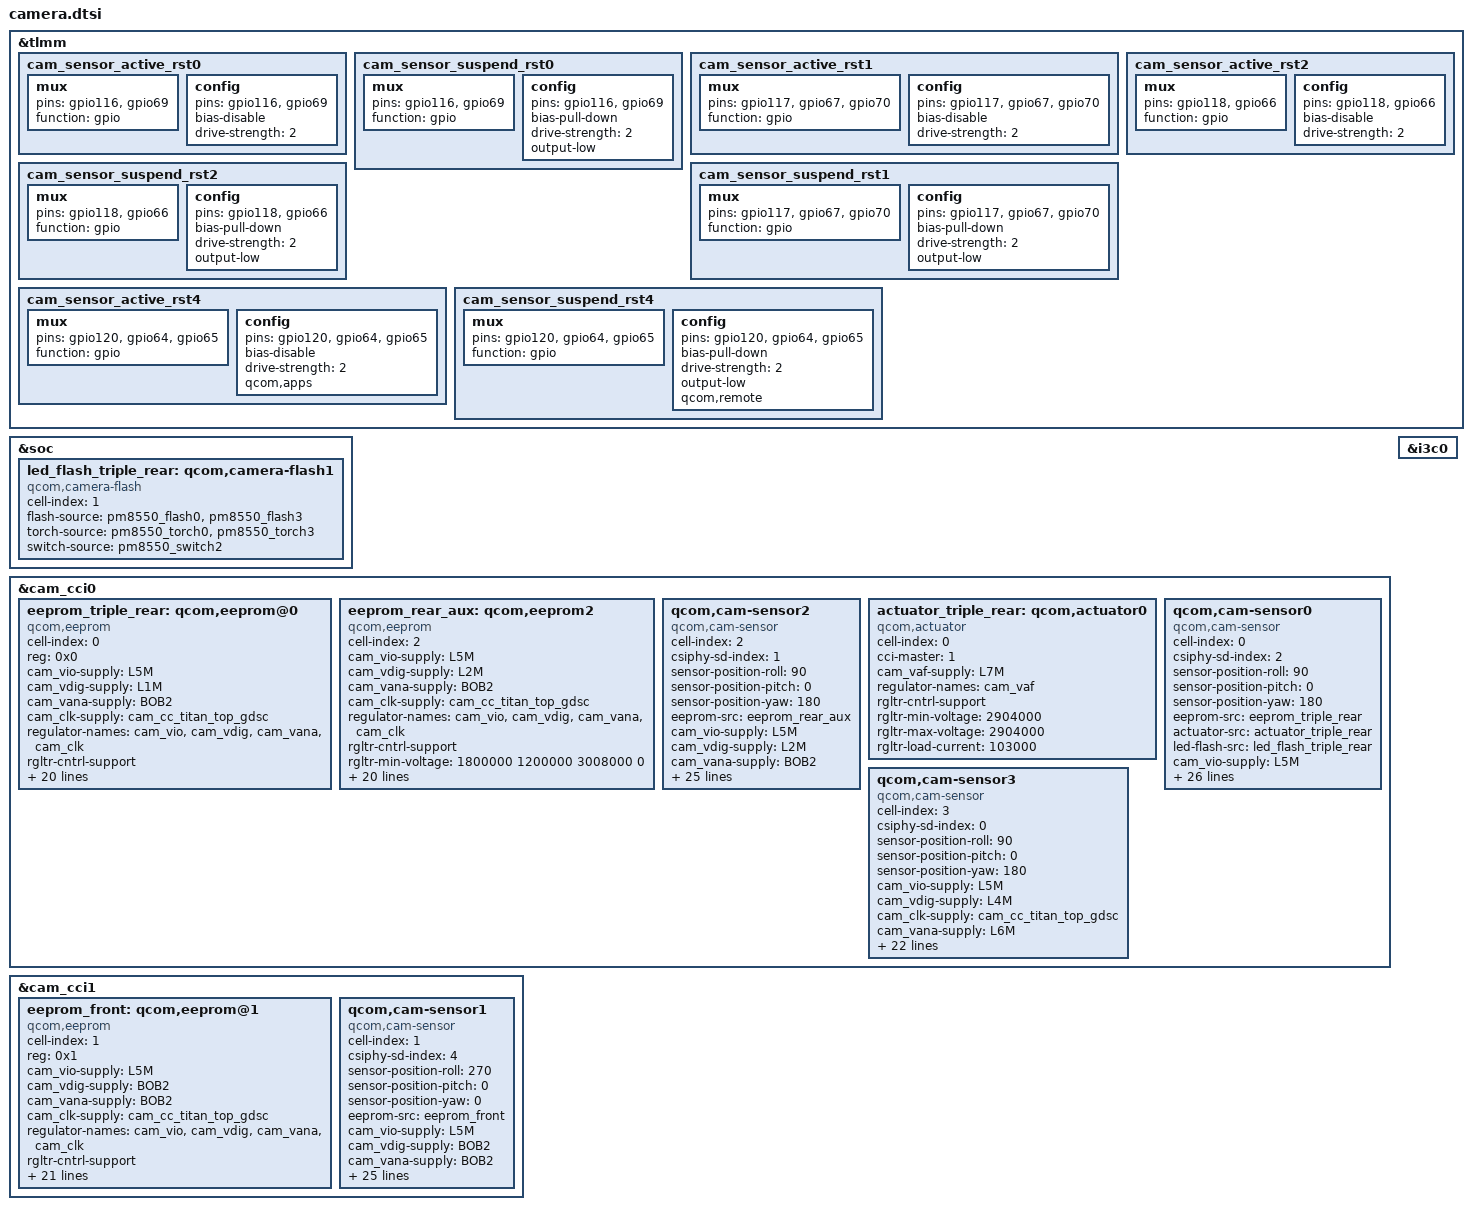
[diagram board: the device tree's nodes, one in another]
//#include <dt-bindings/msm-camera.h>
#include <dt-bindings/clock/qcom,camcc-kalama.h>

&tlmm {
	/delete-node/ cam_sensor_active_rst0;
	/delete-node/ cam_sensor_suspend_rst0;
	/delete-node/ cam_sensor_active_rst1;
	/delete-node/ cam_sensor_suspend_rst1;
	/delete-node/ cam_sensor_active_rst2;
	/delete-node/ cam_sensor_suspend_rst2;
	/delete-node/ cam_sensor_active_rst4;
	/delete-node/ cam_sensor_suspend_rst4;	
	
	cam_sensor_active_rst0: cam_sensor_active_rst0 {
		mux {
			pins = "gpio116","gpio69";
			function = "gpio";
		};

		config {
			pins = "gpio116","gpio69";
			bias-disable; /* No PULL */
			drive-strength = <2>; /* 2 MA */
		};
	};

	cam_sensor_suspend_rst0: cam_sensor_suspend_rst0 {
		mux {
			pins = "gpio116","gpio69";
			function = "gpio";
		};

		config {
			pins = "gpio116","gpio69";
			bias-pull-down; /* PULL DOWN */
			drive-strength = <2>; /* 2 MA */
			output-low;
		};
	};

	cam_sensor_active_rst1: cam_sensor_active_rst1 {
		mux {
			pins = "gpio117","gpio67","gpio70";
			function = "gpio";
		};

		config {
			pins = "gpio117","gpio67","gpio70";
			bias-disable; /* No PULL */
			drive-strength = <2>; /* 2 MA */
		};
	};

	cam_sensor_suspend_rst1: cam_sensor_suspend_rst1 {
		mux {
			pins = "gpio117","gpio67","gpio70";
			function = "gpio";
		};

		config {
			pins = "gpio117","gpio67","gpio70";
			bias-pull-down; /* PULL DOWN */
			drive-strength = <2>; /* 2 MA */
			output-low;
		};
	};

	cam_sensor_active_rst2: cam_sensor_active_rst2 {
		mux {
			pins =  "gpio118","gpio66";
			function = "gpio";
		};

		config {
			pins = "gpio118","gpio66";
			bias-disable; /* No PULL */
			drive-strength = <2>; /* 2 MA */
		};
	};

	cam_sensor_suspend_rst2: cam_sensor_suspend_rst2 {
		mux {
			pins =  "gpio118","gpio66";
			function = "gpio";
		};

		config {
			pins = "gpio118","gpio66";
			bias-pull-down; /* PULL DOWN */
			drive-strength = <2>; /* 2 MA */
			output-low;
		};
	};
		cam_sensor_active_rst4: cam_sensor_active_rst4 {
		mux {
			pins = "gpio120","gpio64","gpio65";
			function = "gpio";
		};

		config {
			pins = "gpio120","gpio64","gpio65";
			bias-disable; /* No PULL */
			drive-strength = <2>; /* 2 MA */
			qcom,apps;
		};
	};

	cam_sensor_suspend_rst4: cam_sensor_suspend_rst4 {
		mux {
			pins = "gpio120","gpio64","gpio65";
			function = "gpio";
		};

		config {
			pins = "gpio120","gpio64","gpio65";
			bias-pull-down; /* PULL DOWN */
			drive-strength = <2>; /* 2 MA */
			output-low;
			qcom,remote;
		};
	};

};


&soc {
	/delete-node/ led_flash_triple_rear_wide;
	/delete-node/ led_flash_triple_rear_tele;
	/delete-node/ led_flash_triple_rear_ultrawide;
	led_flash_triple_rear: qcom,camera-flash1 {
		cell-index = <1>;
		compatible = "qcom,camera-flash";
		flash-source = <&pm8550_flash0 &pm8550_flash3>;
		torch-source = <&pm8550_torch0 &pm8550_torch3>;
		switch-source = <&pm8550_switch2>;
		status = "ok";
	};
};

&cam_cci0 {

	/delete-node/ actuator_triple_uw;
	/delete-node/ actuator_triple_wide;
	/delete-node/ actuator_ois;
	/delete-node/ actuator_hp1;
	/delete-node/ ois0;
	/delete-node/ eeprom_tof1;
	/delete-node/ eeprom_uw;
	/delete-node/ eeprom_wide;
	/delete-node/ eeprom_ois;
	/delete-node/ eeprom_hp1;
	/delete-node/ qcom,cam-sensor7;
	/delete-node/ qcom,cam-sensor1;
	/delete-node/ qcom,cam-sensor2;
	/delete-node/ qcom,cam-sensor9;
	/delete-node/ qcom,cam-sensor0;
	eeprom_triple_rear: qcom,eeprom@0 {
		cell-index = <0>;
		compatible = "qcom,eeprom";
		reg = <0x0>;
		cam_vio-supply = <&L5M>; //dovdd  L5M 1.8v
		cam_vdig-supply = <&L1M>;//dvdd L1M  0.92v
		cam_vana-supply = <&BOB2>;//avdd L3M  2.2v 
		cam_clk-supply = <&cam_cc_titan_top_gdsc>;
		regulator-names = "cam_vio", "cam_vdig", "cam_vana",
			"cam_clk";
		rgltr-cntrl-support;
		rgltr-min-voltage = <1800000 920000 3008000 0>;
		rgltr-max-voltage = <1800000 920000 3960000 0>;
		rgltr-load-current = <10000 140000 7070000 0>;
		gpio-no-mux = <0>;
		pinctrl-names = "cam_default", "cam_suspend";
		pinctrl-0 = <&cam_sensor_mclk2_active
				&cam_sensor_active_rst2>;
		pinctrl-1 = <&cam_sensor_mclk2_suspend
				&cam_sensor_suspend_rst2>;
		gpios = <&tlmm 102 0>,	// mclk  102
		        <&tlmm 118 0>,	// reset  118 		
			<&tlmm 66 0>;	//<&tlmm 66 0>;	

		gpio-reset = <1>;
		gpio-vana = <2>;
		gpio-req-tbl-num = <0 1 2>;
		gpio-req-tbl-flags = <1 0 0>;
		gpio-req-tbl-label = "CAMIF_MCLK0",
					"CAM_RESET0",
					"CAM_VANA0"; //avdd

		cci-master = <1>;
		cci-device = <1>;
		status = "ok";
		clocks = <&camcc CAM_CC_MCLK2_CLK>;
		clock-names = "cam_clk";
		clock-cntl-level = "nominal";
		clock-rates = <19200000>;
	};

//8M eeprom	
    eeprom_rear_aux: qcom,eeprom2 {
	    cell-index = <2>;
	    compatible = "qcom,eeprom";
		cam_vio-supply = <&L5M>; //dovdd  L5M
		cam_vdig-supply = <&L2M>; //dvdd L2M 
		cam_vana-supply = <&BOB2>; //gpio  67
		cam_clk-supply = <&cam_cc_titan_top_gdsc>;
		regulator-names = "cam_vio","cam_vdig","cam_vana","cam_clk";
		rgltr-cntrl-support;
		rgltr-min-voltage = <1800000 1200000 3008000 0>;
		rgltr-max-voltage = <1800000 1200000 3960000 0>;
		rgltr-load-current = <5000   74000   7070000 0>;
		gpio-no-mux = <0>;
		pinctrl-names = "cam_default", "cam_suspend";
		pinctrl-0 = <&cam_sensor_mclk1_active
					 &cam_sensor_active_rst1>;
		pinctrl-1 = <&cam_sensor_mclk1_suspend
					 &cam_sensor_suspend_rst1>;
		gpios = <&tlmm 101 0>, //mclk 101
			<&tlmm 117 0>,//reset  117
			<&tlmm 70 0>,//CAM_STANDBY1  70
			<&tlmm 67 0>; //avdd 67
		gpio-reset = <1>;
		gpio-standby = <2>;
		gpio-vana = <3>;
		gpio-req-tbl-num = <0 1 2 3>;
		gpio-req-tbl-flags = <1 0 0 0>;
		gpio-req-tbl-label = "CAMIF_MCLK1",
							 "CAM_RESET1",
							 "CAM_STANDBY1",
							 "CAM_VANA1";
		cci-master = <0>; //cci  0
		cci-device = <0>;
		clocks = <&camcc CAM_CC_MCLK1_CLK>;
	    clock-names = "cam_clk";
	    clock-cntl-level = "nominal";
	    clock-rates = <19200000>;
	    status = "ok";
    };

//8Mback
	qcom,cam-sensor2 {
		cell-index = <2>;
		compatible = "qcom,cam-sensor";
		csiphy-sd-index = <1>; // csiphy  1
		sensor-position-roll = <90>;
		sensor-position-pitch = <0>;
		sensor-position-yaw = <180>;
		eeprom-src = <&eeprom_rear_aux>;
		cam_vio-supply = <&L5M>; //dovdd  L5M
		cam_vdig-supply = <&L2M>; //dvdd L2M  
		cam_vana-supply = <&BOB2>; //gpio  67
		cam_clk-supply = <&cam_cc_titan_top_gdsc>;
		regulator-names = "cam_vio","cam_vdig","cam_vana","cam_clk";
		rgltr-cntrl-support;
		rgltr-min-voltage = <1800000 1200000 3008000 0>;
		rgltr-max-voltage = <1800000 1200000 3960000 0>;
		rgltr-load-current = <5000   74000   7070000 0>;
		gpio-no-mux = <0>;
		pinctrl-names = "cam_default", "cam_suspend";
		pinctrl-0 = <&cam_sensor_mclk1_active
					 &cam_sensor_active_rst1>;
		pinctrl-1 = <&cam_sensor_mclk1_suspend
					 &cam_sensor_suspend_rst1>;
		gpios = <&tlmm 101 0>, //mclk 101
			<&tlmm 117 0>,//reset  117
			<&tlmm 70 0>,//CAM_STANDBY1  70
			<&tlmm 67 0>; //avdd 67
		gpio-reset = <1>;
		gpio-standby = <2>;
		gpio-vana = <3>;
		gpio-req-tbl-num = <0 1 2 3>;
		gpio-req-tbl-flags = <1 0 0 0>;
		gpio-req-tbl-label = "CAMIF_MCLK1",
							 "CAM_RESET1",
							 "CAM_STANDBY1",
							 "CAM_VANA1";
		cci-master = <0>; //cci  0
		cci-device = <0>;
		status = "ok";
		clocks = <&camcc CAM_CC_MCLK1_CLK>;
		clock-names = "cam_clk";
		clock-cntl-level = "nominal";
		clock-rates = <19200000>;
	};
	actuator_triple_rear: qcom,actuator0 {
		cell-index = <0>;
		compatible = "qcom,actuator";
		cci-master = <1>;
		cam_vaf-supply = <&L7M>;
		regulator-names = "cam_vaf";
		rgltr-cntrl-support;
		rgltr-min-voltage = <2904000>;
		rgltr-max-voltage = <2904000>;
		rgltr-load-current = <103000>;
		status = "ok";
	};
	qcom,cam-sensor0 {
		cell-index = <0>;
		compatible = "qcom,cam-sensor";
		csiphy-sd-index = <2>;
		sensor-position-roll = <90>;
		sensor-position-pitch = <0>;
		sensor-position-yaw = <180>;
		eeprom-src = <&eeprom_triple_rear>;
		actuator-src = <&actuator_triple_rear>;
		led-flash-src = <&led_flash_triple_rear>;
		cam_vio-supply = <&L5M>; //dovdd  L5M 1.8v
		cam_vdig-supply = <&L1M>;//dvdd L1M 
		cam_vana-supply = <&BOB2>;//avdd L3M  2.2v 
		cam_clk-supply = <&cam_cc_titan_top_gdsc>;
		regulator-names = "cam_vio", "cam_vdig", "cam_vana",
			"cam_clk";
		rgltr-cntrl-support;
		rgltr-min-voltage = <1800000 920000 3008000 0>;
		rgltr-max-voltage = <1800000 920000 3960000 0>;
		rgltr-load-current = <10000 140000 7070000 0>;
		gpio-no-mux = <0>;
		pinctrl-names = "cam_default", "cam_suspend";
		pinctrl-0 = <&cam_sensor_mclk2_active
				&cam_sensor_active_rst2>;
		pinctrl-1 = <&cam_sensor_mclk2_suspend
				&cam_sensor_suspend_rst2>;
		gpios = <&tlmm 102 0>,	// mclk  102
		        <&tlmm 118 0>,	// reset  118 		
			<&tlmm 66 0>;	//<&tlmm 66 0>;	

		gpio-reset = <1>;
		gpio-vana = <2>;
		gpio-req-tbl-num = <0 1 2>;
		gpio-req-tbl-flags = <1 0 0>;
		gpio-req-tbl-label = "CAMIF_MCLK0",
					"CAM_RESET0",
					"CAM_VANA0"; //avdd

		cci-master = <1>;
		cci-device = <1>;
		status = "ok";
		clocks = <&camcc CAM_CC_MCLK2_CLK>;
		clock-names = "cam_clk";
		clock-cntl-level = "nominal";
		clock-rates = <19200000>;
	};
//2M
	qcom,cam-sensor3 {
		cell-index = <3>;
		compatible = "qcom,cam-sensor";
		csiphy-sd-index = <0>;
		sensor-position-roll = <90>;
		sensor-position-pitch = <0>;
		sensor-position-yaw = <180>;
		//eeprom-src = <&eeprom_tele>;
		//actuator-src = <&actuator_triple_tele>;
		//led-flash-src = <&led_flash_triple_rear_tele>;
		cam_vio-supply = <&L5M>;//dovdd
		cam_vdig-supply = <&L4M>;//dvdd
		cam_clk-supply = <&cam_cc_titan_top_gdsc>;
		cam_vana-supply = <&L6M>;//avdd
		//cam_vaf-supply = <&L7N>;
		regulator-names = "cam_vio", "cam_vdig","cam_clk","cam_vana";
		rgltr-cntrl-support;
		rgltr-min-voltage = <1800000 1800000 0 2800000>;
		rgltr-max-voltage = <1800000 1800000 0 2800000>;
		rgltr-load-current = <10000 10000 0 52000>;
		gpio-no-mux = <0>;
		pinctrl-names = "cam_default", "cam_suspend";
		pinctrl-0 = <&cam_sensor_mclk0_active
			&cam_sensor_active_rst0>;
		pinctrl-1 = <&cam_sensor_mclk0_suspend
			&cam_sensor_suspend_rst0>;
		gpios = <&tlmm 100 0>,
		      <&tlmm 116 0>,
		      <&tlmm 69 0>;
		gpio-reset = <1>;
		gpio-vana = <2>;
		gpio-req-tbl-num = <0 1 2>;
		gpio-req-tbl-flags = <1 0 0>;
		gpio-req-tbl-label = "CAMIF_MCLK0",
			"CAM_RESET0",
			"CAM_VANA0";
		cci-master = <0>;
		clocks = <&camcc CAM_CC_MCLK0_CLK>;
		clock-names = "cam_clk";
		clock-cntl-level = "nominal";
		clock-rates = <24000000>;
		status = "ok";
	};
};

&cam_cci1 {

	/delete-node/ actuator_triple_tele;
	/delete-node/ eeprom_tele;
	/delete-node/ eeprom_aon_front;
	/delete-node/ qcom,cam-sensor3;
	/delete-node/ qcom,cam-sensor4;
	eeprom_front: qcom,eeprom@1 {
		cell-index = <1>;
		compatible = "qcom,eeprom";
		reg = <0x1>;
		cam_vio-supply = <&L5M>; // dovdd  L5M
		cam_vdig-supply = <&BOB2>;//DBO3  dvdd  gpio 65
		cam_vana-supply = <&BOB2>;//DBO3 avdd gpio   64
		cam_clk-supply = <&cam_cc_titan_top_gdsc>;
		regulator-names = "cam_vio","cam_vdig","cam_vana","cam_clk";
		rgltr-cntrl-support;
		rgltr-min-voltage = <1800000 3008000 3008000 0>;
		rgltr-max-voltage = <1800000 3960000 3960000 0>;
		rgltr-load-current = <5000 5000 7070000 0>;
		gpio-no-mux = <0>;
		pinctrl-names = "cam_default", "cam_suspend";
		pinctrl-0 = <&cam_sensor_mclk4_active
				 &cam_sensor_active_rst4>;
		pinctrl-1 = <&cam_sensor_mclk4_suspend
				 &cam_sensor_suspend_rst4>;
		gpios = <&tlmm 104 0>, //  mclk   104
			<&tlmm 120 0>,//reset 120
			<&tlmm 64 0>, //van 64
			<&tlmm 65 0>; //dvdd  gpio 65
	
		gpio-reset = <1>;
		gpio-vana = <2>;
		gpio-standby = <3>;
		gpio-req-tbl-num = <0 1 2 3>;
		gpio-req-tbl-flags = <1 0 0 0>;
		gpio-req-tbl-label = "CAMIF_MCLK4",
					"CAM_RESET4",
					"CAM_VANA4",
					"CAM_STANDBY5";

		cci-master = <0>; //cci 2
		cci-device = <0>;
		status = "ok";
		clocks = <&camcc CAM_CC_MCLK4_CLK>;
		clock-names = "cam_clk";
		clock-cntl-level = "nominal";
		clock-rates = <19200000>;
	};

	qcom,cam-sensor1 {
		cell-index = <1>;
		compatible = "qcom,cam-sensor";
		csiphy-sd-index = <4>; // csiphy  4
		sensor-position-roll = <270>;
		sensor-position-pitch = <0>;
		sensor-position-yaw = <0>;
		eeprom-src = <&eeprom_front>;
		cam_vio-supply = <&L5M>; // dovdd  L5M
		cam_vdig-supply = <&BOB2>;//DBO3  dvdd  gpio 65
		cam_vana-supply = <&BOB2>;//DBO3 avdd gpio   64
		cam_clk-supply = <&cam_cc_titan_top_gdsc>;
		regulator-names = "cam_vio","cam_vdig","cam_vana","cam_clk";
		rgltr-cntrl-support;
		rgltr-min-voltage = <1800000 3008000 3008000 0>;
		rgltr-max-voltage = <1800000 3960000 3960000 0>;
		rgltr-load-current = <5000 5000 7070000 0>;
		gpio-no-mux = <0>;
		pinctrl-names = "cam_default", "cam_suspend";
		pinctrl-0 = <&cam_sensor_mclk4_active
				 &cam_sensor_active_rst4>;
		pinctrl-1 = <&cam_sensor_mclk4_suspend
				 &cam_sensor_suspend_rst4>;
		gpios = <&tlmm 104 0>, //  mclk   104
			<&tlmm 120 0>,//reset 120
			<&tlmm 64 0>, //van 64
			<&tlmm 65 0>; //dvdd  gpio 65
	
		gpio-reset = <1>;
		gpio-vana = <2>;
		gpio-standby = <3>;
		gpio-req-tbl-num = <0 1 2 3>;
		gpio-req-tbl-flags = <1 0 0 0>;
		gpio-req-tbl-label = "CAMIF_MCLK4",
					"CAM_RESET4",
					"CAM_VANA4",
					"CAM_STANDBY5";

		cci-master = <0>; //cci 2
		cci-device = <0>;
		status = "ok";
		clocks = <&camcc CAM_CC_MCLK4_CLK>;
		clock-names = "cam_clk";
		clock-cntl-level = "nominal";
		clock-rates = <19200000>;
	};
};
&cam_cci1 {
    /delete-node/ eeprom_tof2;
    /delete-node/ qcom,cam-sensor5;  
};
&i3c0 {
    /delete-node/ actuator_i3c_triple_wide;
	/delete-node/ eeprom_i3c_wide;
	/delete-node/ qcom,cam-sensor@34,36007660000;
};
	


